# ATSAMA5D27WLSOM1 device description
Architecture: CORTEX-A5; Family: SAMA5; Series: SAMA5D2
Registers are 32-bit, read-write, no defined reset value unless marked. A register's access mark holds for its fields unless they carry their own. Offsets are from the block's base; [hi:lo] are bit positions; lines under a group give offsets from that group; {n}, {i} and the like mark numbered series; 'fields as' and 'values as' point back to an identical list; <NAME> marks a mode.

## RTC — Real-time Clock
Instances: RTC 0xF80480B0
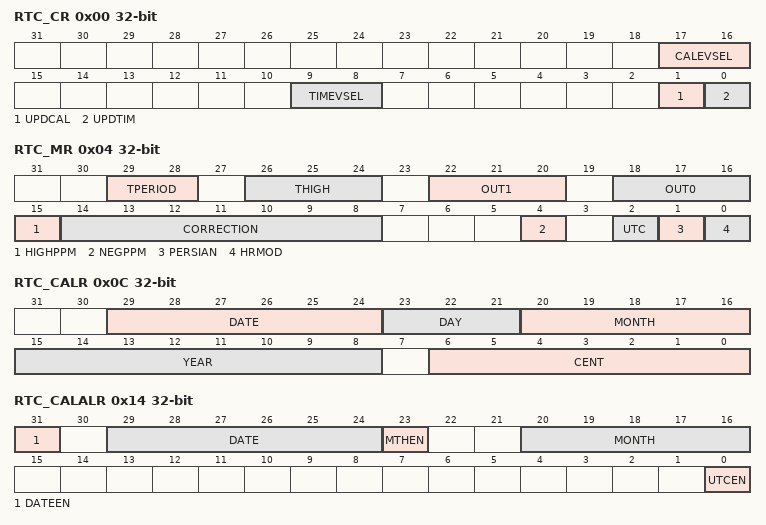
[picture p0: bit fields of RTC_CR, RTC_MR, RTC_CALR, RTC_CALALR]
0x00 RTC_CR — Control Register
  [17:16] CALEVSEL — Calendar Event Selection
    0=WEEK (Week change (every Monday at time 00:00:00)); 1=MONTH (Month change (every 01 of each month at time 00:00:00)); 2=YEAR (Year change (every January 1 at time 00:00:00))
  [9:8] TIMEVSEL — Time Event Selection
    0=MINUTE (Minute change); 1=HOUR (Hour change); 2=MIDNIGHT (Every day at midnight); 3=NOON (Every day at noon)
  [1] UPDCAL — Update Request Calendar Register
  [0] UPDTIM — Update Request Time Register
0x04 RTC_MR — Mode Register
  [29:28] TPERIOD — Period of the Output Pulse
    0=P_1S (1 second); 1=P_500MS (500 ms); 2=P_250MS (250 ms); 3=P_125MS (125 ms)
  [26:24] THIGH — High Duration of the Output Pulse
    0=H_31MS (31.2 ms); 1=H_16MS (15.6 ms); 2=H_4MS (3.91 ms); 3=H_976US (976 us); 4=H_488US (488 us); 5=H_122US (122 us); 6=H_30US (30.5 us); 7=H_15US (15.2 us)
  [22:20] OUT1 — ADC Last Channel Trigger Event Source Selection
    0=NO_WAVE (No waveform, stuck at '0'); 1=FREQ1HZ (1 Hz square wave); 2=FREQ32HZ (32 Hz square wave); 3=FREQ64HZ (64 Hz square wave); 4=FREQ512HZ (512 Hz square wave); 5=ALARM_TOGGLE (Output toggles when alarm flag rises); 6=ALARM_FLAG (Output is a copy of the alarm flag); 7=PROG_PULSE (Duty cycle programmable pulse)
  [18:16] OUT0 — All ADC Channel Trigger Event Source Selection
    values as OUT1
  [15] HIGHPPM — HIGH PPM Correction
  [14:8] CORRECTION — Slow Clock Correction
  [4] NEGPPM — NEGative PPM Correction
  [2] UTC — UTC Time Format
  [1] PERSIAN — PERSIAN Calendar
  [0] HRMOD — 12-/24-hour Mode
0x08 RTC_TIMR (modes: DEFAULT when RTC_MR.UTC=0; UTC_MODE when RTC_MR.UTC=0) — Time Register
  [22] AMPM <DEFAULT> — Ante Meridiem Post Meridiem Indicator
  [21:16] HOUR <DEFAULT> — Current Hour
  [14:8] MIN <DEFAULT> — Current Minute
  [6:0] SEC <DEFAULT> — Current Second
  [31:0] UTC_TIME <UTC_MODE> — Current UTC Time
0x0C RTC_CALR — Calendar Register
  [29:24] DATE — Current Day in Current Month
  [23:21] DAY — Current Day in Current Week
  [20:16] MONTH — Current Month
  [15:8] YEAR — Current Year
  [6:0] CENT — Current Century
0x10 RTC_TIMALR (modes: DEFAULT when RTC_MR.UTC=0; UTC_MODE when RTC_MR.UTC=0) — Time Alarm Register
  [23] HOUREN <DEFAULT> — Hour Alarm Enable
  [22] AMPM <DEFAULT> — AM/PM Indicator
  [21:16] HOUR <DEFAULT> — Hour Alarm
  [15] MINEN <DEFAULT> — Minute Alarm Enable
  [14:8] MIN <DEFAULT> — Minute Alarm
  [7] SECEN <DEFAULT> — Second Alarm Enable
  [6:0] SEC <DEFAULT> — Second Alarm
  [31:0] UTC_TIME <UTC_MODE> — UTC_TIME Alarm
0x14 RTC_CALALR (modes: DEFAULT when RTC_MR.UTC=0; UTC_MODE when RTC_MR.UTC=0) — Calendar Alarm Register
  [31] DATEEN <DEFAULT> — Date Alarm Enable
  [29:24] DATE <DEFAULT> — Date Alarm
  [23] MTHEN <DEFAULT> — Month Alarm Enable
  [20:16] MONTH <DEFAULT> — Month Alarm
  [0] UTCEN <UTC_MODE> — UTC Alarm Enable
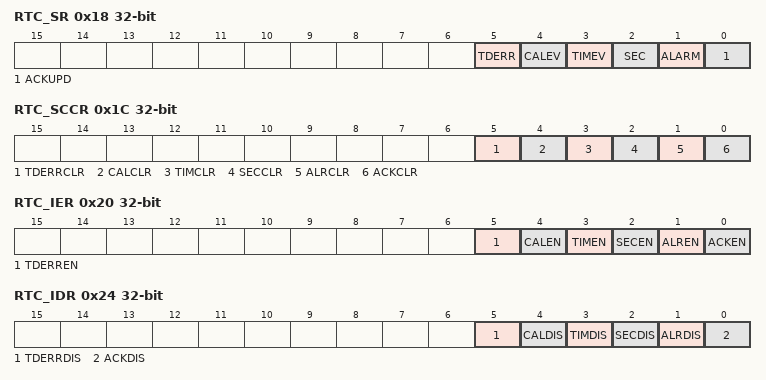
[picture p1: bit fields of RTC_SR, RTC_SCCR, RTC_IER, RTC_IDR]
0x18 RTC_SR ro — Status Register
  [5] TDERR — Time and/or Date Free Running Error
    0=CORRECT (The internal free running counters are carrying valid values since the last read of the Status Register (RTC_SR).); 1=ERR_TIMEDATE (The internal free running counters have been corrupted (invalid date or time, non-BCD values) since the last read and/or they are still invalid.)
  [4] CALEV — Calendar Event
    0=NO_CALEVENT (No calendar event has occurred since the last clear.); 1=CALEVENT (At least one calendar event has occurred since the last clear.)
  [3] TIMEV — Time Event
    0=NO_TIMEVENT (No time event has occurred since the last clear.); 1=TIMEVENT (At least one time event has occurred since the last clear.)
  [2] SEC — Second Event
    0=NO_SECEVENT (No second event has occurred since the last clear.); 1=SECEVENT (At least one second event has occurred since the last clear.)
  [1] ALARM — Alarm Flag
    0=NO_ALARMEVENT (No alarm matching condition occurred.); 1=ALARMEVENT (An alarm matching condition has occurred.)
  [0] ACKUPD — Acknowledge for Update
    0=FREERUN (Time and calendar registers cannot be updated.); 1=UPDATE (Time and calendar registers can be updated.)
0x1C RTC_SCCR wo — Status Clear Command Register
  [5] TDERRCLR — Time and/or Date Free Running Error Clear
  [4] CALCLR — Calendar Clear
  [3] TIMCLR — Time Clear
  [2] SECCLR — Second Clear
  [1] ALRCLR — Alarm Clear
  [0] ACKCLR — Acknowledge Clear
0x20 RTC_IER wo (atomic set of RTC_IMR) — Interrupt Enable Register
  [5] TDERREN — Time and/or Date Error Interrupt Enable
  [4] CALEN — Calendar Event Interrupt Enable
  [3] TIMEN — Time Event Interrupt Enable
  [2] SECEN — Second Event Interrupt Enable
  [1] ALREN — Alarm Interrupt Enable
  [0] ACKEN — Acknowledge Update Interrupt Enable
0x24 RTC_IDR wo (atomic clear of RTC_IMR) — Interrupt Disable Register
  [5] TDERRDIS — Time and/or Date Error Interrupt Disable
  [4] CALDIS — Calendar Event Interrupt Disable
  [3] TIMDIS — Time Event Interrupt Disable
  [2] SECDIS — Second Event Interrupt Disable
  [1] ALRDIS — Alarm Interrupt Disable
  [0] ACKDIS — Acknowledge Update Interrupt Disable
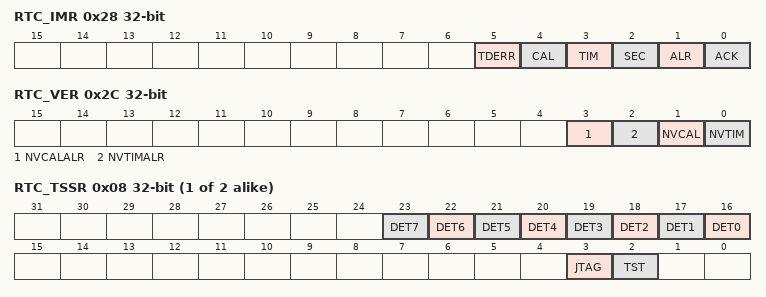
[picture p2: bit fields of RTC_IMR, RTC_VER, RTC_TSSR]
0x28 RTC_IMR ro (atomic read) — Interrupt Mask Register
  [5] TDERR — Time and/or Date Error Mask
  [4] CAL — Calendar Event Interrupt Mask
  [3] TIM — Time Event Interrupt Mask
  [2] SEC — Second Event Interrupt Mask
  [1] ALR — Alarm Interrupt Mask
  [0] ACK — Acknowledge Update Interrupt Mask
0x2C RTC_VER ro — Valid Entry Register
  [3] NVCALALR — Non-valid Calendar Alarm
  [2] NVTIMALR — Non-valid Time Alarm
  [1] NVCAL — Non-valid Calendar
  [0] NVTIM — Non-valid Time
{0xB0+0xC*i} RTC_TS[{i}] (i=0..1) group
  0x00 RTC_TSTR ro (modes: DEFAULT when RTC_MR.UTC=0; UTC_MODE when RTC_MR.UTC=0) — TimeStamp Time Register 0
    [31] BACKUP <DEFAULT> — System Mode of the Tamper
    [27:24] TEVCNT <DEFAULT> — Tamper Events Counter
    [22] AMPM <DEFAULT> — AM/PM Indicator of the Tamper
    [21:16] HOUR <DEFAULT> — Hours of the Tamper
    [14:8] MIN <DEFAULT> — Minutes of the Tamper
    [6:0] SEC <DEFAULT> — Seconds of the Tamper
    [31] BACKUP <UTC_MODE> — System Mode of the Tamper (cleared by reading RTC_TSSR0)
    [27:24] TEVCNT <UTC_MODE> — Tamper Events Counter (cleared by reading RTC_TSSR0)
  0x04 RTC_TSDR ro (modes: DEFAULT when RTC_MR.UTC=0; UTC_MODE when RTC_MR.UTC=0) — TimeStamp Date Register 0
    [29:24] DATE <DEFAULT> — Date of the Tamper
    [23:21] DAY <DEFAULT> — Day of the Tamper
    [20:16] MONTH <DEFAULT> — Month of the Tamper
    [15:8] YEAR <DEFAULT> — Year of the Tamper
    [6:0] CENT <DEFAULT> — Century of the Tamper
    [31:0] UTC_TIME <UTC_MODE> — Time of the Tamper (UTC format)
  0x08 RTC_TSSR ro — TimeStamp Source Register 0
    [n+16] DET{n} (n=0..7) — PIOBU Intrusion Detector
    [3] JTAG — JTAG Pins Monitor
    [2] TST — Test Pin Monitor
